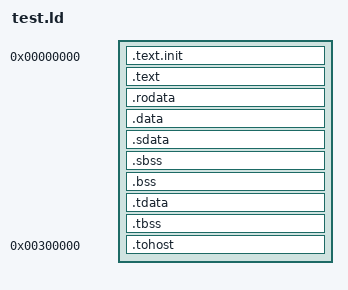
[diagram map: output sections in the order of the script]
OUTPUT_ARCH( "riscv" )
ENTRY(rvtest_entry_point)

SECTIONS
{
  . = 0x0;
  .text.init : { *(.text.init) }
  .text : { *(.text) }
  .rodata : { *(.rodata) }
  .data : { *(.data) }
  .sdata : {
    __global_pointer$ = . + 0x800;
    *(.srodata.cst16) *(.srodata.cst8) *(.srodata.cst4) *(.srodata.cst2) *(.srodata*)
    *(.sdata .sdata.* .gnu.linkonce.s.*)
  }
  .sbss : {
    *(.sbss .sbss.* .gnu.linkonce.sb.*)
    *(.scommon)
  }
  .bss : { *(.bss) }
  .tdata :
  {
    _tdata_begin = .;
    *(.tdata)
    _tdata_end = .;
  }
  .tbss :
  {
    *(.tbss)
    _tbss_end = .;
  }
  _end = .;
  . = 0x300000;
  .tohost : { *(.tohost) }
}
